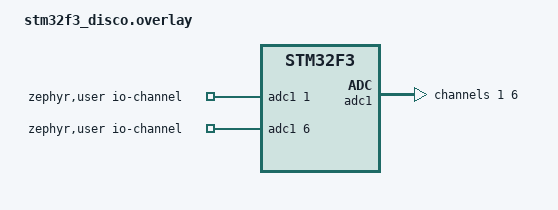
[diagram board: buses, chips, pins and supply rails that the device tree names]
/*
 * Copyright (c) 2021 Nordic Semiconductor ASA
 * SPDX-License-Identifier: Apache-2.0
 */

/* This devicetree overlay file will be automatically picked by the Zephyr
 * build system when building the sample for the nucleo_f302r8 board. It shows
 * how the example-application can be built on sample boards already provided
 * by Zephyr.
 */

&gpioc {
	status = "okay";
};

/{
	zephyr,user {
		io-channels = <&adc1 1>, <&adc1 6>;
	};
};

&adc1 {
	#address-cells = <1>;
	#size-cells = <0>;

	channel@1 {
		reg = <1>;
		zephyr,gain = "ADC_GAIN_1";
		zephyr,reference = "ADC_REF_INTERNAL";
		zephyr,acquisition-time = <ADC_ACQ_TIME_DEFAULT>;
		zephyr,resolution = <12>;
	};

	channel@6 {
		reg = <6>;
		zephyr,gain = "ADC_GAIN_1";
		zephyr,reference = "ADC_REF_INTERNAL";
		zephyr,acquisition-time = <ADC_ACQ_TIME_DEFAULT>;
		zephyr,resolution = <12>;
	};
};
